# MK11DA5 register map
Vendor: Freescale Semiconductor, Inc.; Series: Kinetis_K; File version: 1.6
CPU: CM4 r0p1, little endian, no MPU, no FPU, VTOR, 4 interrupt priority bits
Registers are 8-bit, read-write, reset 0x0 unless marked. A register's access mark holds for its fields unless they carry their own. Offsets are from the block's base; [hi:lo] are bit positions; {n}, {i} and the like mark numbered series; 'fields as' and 'values as' point back to an identical list.

## GPIOA — General Purpose Input/Output
Base 0x400FF000; register names take the prefix GPIOA_
0x00 PDOR 32-bit — Port Data Output Register
  [31:0] PDO — Port Data Output
    0=Logic level 0 is driven on pin, provided pin is configured for general-purpose output; 1=Logic level 1 is driven on pin, provided pin is configured for general-purpose output
0x04 PSOR 32-bit wo — Port Set Output Register
  [31:0] PTSO — Port Set Output
    0=Corresponding bit in PDORn does not change; 1=Corresponding bit in PDORn is set to logic 1
0x08 PCOR 32-bit wo — Port Clear Output Register
  [31:0] PTCO — Port Clear Output
    0=Corresponding bit in PDORn does not change; 1=Corresponding bit in PDORn is cleared to logic 0
0x0C PTOR 32-bit wo — Port Toggle Output Register
  [31:0] PTTO — Port Toggle Output
    0=Corresponding bit in PDORn does not change; 1=Corresponding bit in PDORn is set to the inverse of its existing logic state
0x10 PDIR 32-bit ro — Port Data Input Register
  [31:0] PDI — Port Data Input
    0=Pin logic level is logic 0, or is not configured for use by digital function; 1=Pin logic level is logic 1
0x14 PDDR 32-bit — Port Data Direction Register
  [31:0] PDD — Port Data Direction
    0=Pin is configured as general-purpose input, for the GPIO function; 1=Pin is configured as general-purpose output, for the GPIO function

## GPIOB — General Purpose Input/Output
Base 0x400FF040; register names take the prefix GPIOB_
Registers as GPIOA.

## GPIOC — General Purpose Input/Output
Base 0x400FF080; register names take the prefix GPIOC_
Registers as GPIOA.

## GPIOD — General Purpose Input/Output
Base 0x400FF0C0; register names take the prefix GPIOD_
Registers as GPIOA.

## GPIOE — General Purpose Input/Output
Base 0x400FF100; register names take the prefix GPIOE_
Registers as GPIOA.

## SysTick — System timer
Base 0xE000E010; register names take the prefix SYST_
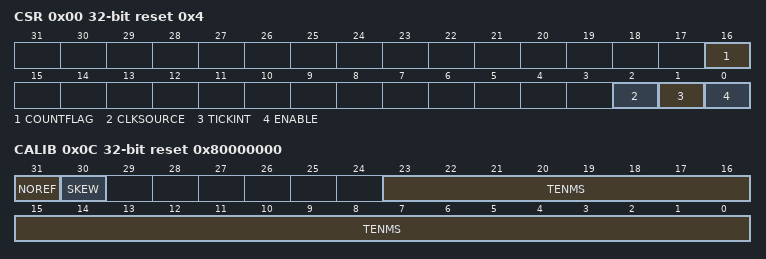
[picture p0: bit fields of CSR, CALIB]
0x00 CSR 32-bit reset 0x4 — SysTick Control and Status Register
  [16] COUNTFLAG
  [2] CLKSOURCE
    0=external clock; 1=processor clock
  [1] TICKINT
    0=counting down to 0 does not assert the SysTick exception request; 1=counting down to 0 asserts the SysTick exception request
  [0] ENABLE
    0=counter disabled; 1=counter enabled
0x04 RVR 32-bit — SysTick Reload Value Register
  [23:0] RELOAD — Value to load into the SysTick Current Value Register when the counter reaches 0
0x08 CVR 32-bit — SysTick Current Value Register
  [23:0] CURRENT — Current value at the time the register is accessed
0x0C CALIB 32-bit ro reset 0x80000000 — SysTick Calibration Value Register
  [31] NOREF
    0=The reference clock is provided; 1=The reference clock is not provided
  [30] SKEW
    0=10ms calibration value is exact; 1=10ms calibration value is inexact, because of the clock frequency
  [23:0] TENMS — Reload value to use for 10ms timing

## MCM — Core Platform Miscellaneous Control Module
Base 0xE0080000; register names take the prefix MCM_
0x08 PLASC 16-bit ro reset 0xF — Crossbar Switch (AXBS) Slave Configuration
  [7:0] ASC — Each bit in the ASC field indicates whether there is a corresponding connection to the crossbar switch's slave input port.
    0=A bus slave connection to AXBS input port n is absent; 1=A bus slave connection to AXBS input port n is present
0x0A PLAMC 16-bit ro reset 0x13 — Crossbar Switch (AXBS) Master Configuration
  [7:0] AMC — Each bit in the AMC field indicates whether there is a corresponding connection to the AXBS master input port.
    0=A bus master connection to AXBS input port n is absent; 1=A bus master connection to AXBS input port n is present
0x0C PLACR 32-bit — Crossbar Switch (AXBS) Control Register
  [9] ARB — Arbitration select
    0=Fixed-priority arbitration for the crossbar masters; 1=Round-robin arbitration for the crossbar masters

## CAU — Memory Mapped Cryptographic Acceleration Unit (MMCAU)
Base 0xE0081000
{0x0+4i} CAU_DIRECT{i} 32-bit wo (i=0..15) — Direct access register {i}
  [31:0] CAU_DIRECT{i} — Direct register {i}
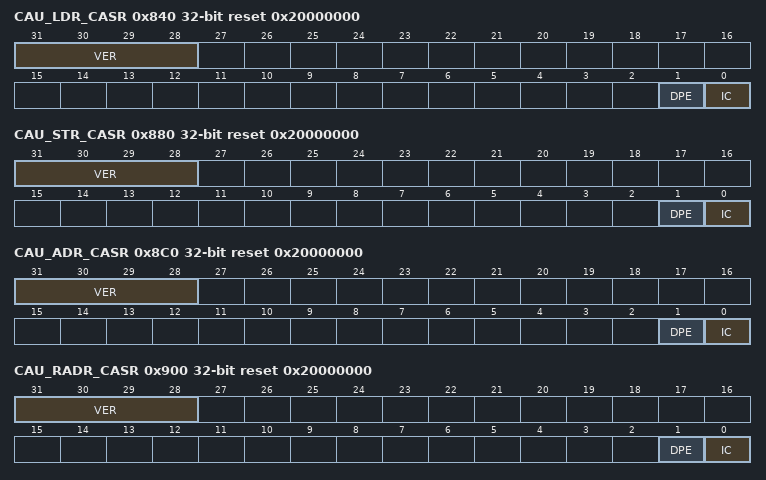
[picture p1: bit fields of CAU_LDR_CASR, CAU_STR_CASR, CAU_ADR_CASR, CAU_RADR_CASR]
0x840 CAU_LDR_CASR 32-bit wo reset 0x20000000 — Status register - Load Register command
  [31:28] VER — CAU version
    1=Initial CAU version; 2=Second version, added support for SHA-256 algorithm.(This is the value on this device)
  [1] DPE
    0=No error detected; 1=DES key parity error detected
  [0] IC
    0=No illegal commands issued; 1=Illegal command issued
0x844 CAU_LDR_CAA 32-bit wo — Accumulator register - Load Register command
  [31:0] ACC
{0x848+4i} CAU_LDR_CA{i} 32-bit wo (i=0..8) — General Purpose Register {i} - Load Register command
0x880 CAU_STR_CASR 32-bit ro reset 0x20000000 — Status register - Store Register command
  fields as CAU_LDR_CASR
0x884 CAU_STR_CAA 32-bit ro — Accumulator register - Store Register command
  [31:0] ACC
{0x888+4i} CAU_STR_CA{i} 32-bit ro (i=0..8) — General Purpose Register {i} - Store Register command
0x8C0 CAU_ADR_CASR 32-bit wo reset 0x20000000 — Status register - Add Register command
  fields as CAU_LDR_CASR
0x8C4 CAU_ADR_CAA 32-bit wo — Accumulator register - Add to register command
  [31:0] ACC
{0x8C8+4i} CAU_ADR_CA{i} 32-bit wo (i=0..8) — General Purpose Register {i} - Add to register command
0x900 CAU_RADR_CASR 32-bit wo reset 0x20000000 — Status register - Reverse and Add to Register command
  fields as CAU_LDR_CASR
0x904 CAU_RADR_CAA 32-bit wo — Accumulator register - Reverse and Add to Register command
  [31:0] ACC
{0x908+4i} CAU_RADR_CA{i} 32-bit wo (i=0..8) — General Purpose Register {i} - Reverse and Add to Register command
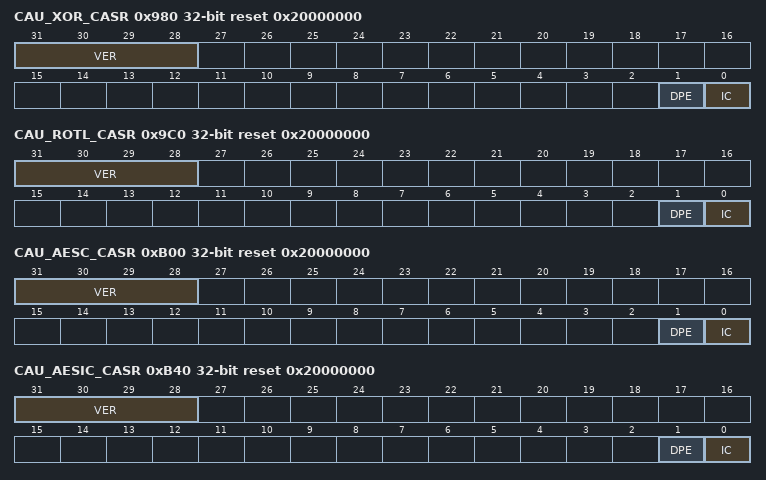
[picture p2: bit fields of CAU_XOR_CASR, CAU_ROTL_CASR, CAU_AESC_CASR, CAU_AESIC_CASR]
0x980 CAU_XOR_CASR 32-bit wo reset 0x20000000 — Status register - Exclusive Or command
  fields as CAU_LDR_CASR
0x984 CAU_XOR_CAA 32-bit wo — Accumulator register - Exclusive Or command
  [31:0] ACC
{0x988+4i} CAU_XOR_CA{i} 32-bit wo (i=0..8) — General Purpose Register {i} - Exclusive Or command
0x9C0 CAU_ROTL_CASR 32-bit wo reset 0x20000000 — Status register - Rotate Left command
  fields as CAU_LDR_CASR
0x9C4 CAU_ROTL_CAA 32-bit wo — Accumulator register - Rotate Left command
  [31:0] ACC
{0x9C8+4i} CAU_ROTL_CA{i} 32-bit wo (i=0..8) — General Purpose Register {i} - Rotate Left command
0xB00 CAU_AESC_CASR 32-bit wo reset 0x20000000 — Status register - AES Column Operation command
  fields as CAU_LDR_CASR
0xB04 CAU_AESC_CAA 32-bit wo — Accumulator register - AES Column Operation command
  [31:0] ACC
{0xB08+4i} CAU_AESC_CA{i} 32-bit wo (i=0..8) — General Purpose Register {i} - AES Column Operation command
0xB40 CAU_AESIC_CASR 32-bit wo reset 0x20000000 — Status register - AES Inverse Column Operation command
  fields as CAU_LDR_CASR
0xB44 CAU_AESIC_CAA 32-bit wo — Accumulator register - AES Inverse Column Operation command
  [31:0] ACC
{0xB48+4i} CAU_AESIC_CA{i} 32-bit wo (i=0..8) — General Purpose Register {i} - AES Inverse Column Operation command
